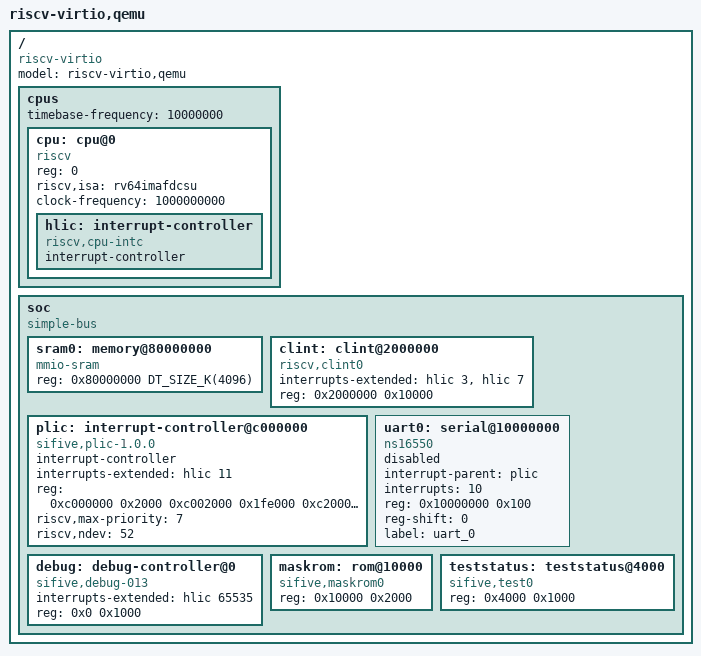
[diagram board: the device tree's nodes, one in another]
/* SPDX-License-Identifier: Apache-2.0 */

#include <mem.h>

/ {
	#address-cells = <1>;
	#size-cells = <1>;
	compatible = "riscv-virtio";
	model = "riscv-virtio,qemu";

	cpus {
		#address-cells = <1>;
		#size-cells = <0>;
		timebase-frequency = <10000000>;

		cpu: cpu@0 {
			device_type = "cpu";
			reg = <0>;
			status = "okay";
			compatible = "riscv";
			riscv,isa = "rv64imafdcsu";
			clock-frequency = <1000000000>;

			hlic: interrupt-controller {
				#interrupt-cells = <1>;
				interrupt-controller;
				compatible = "riscv,cpu-intc";
			};
		};
	};
	soc {
		#address-cells = <1>;
		#size-cells = <1>;
		compatible = "simple-bus";
		ranges;

		sram0: memory@80000000 {
			compatible = "mmio-sram";
			device_type = "memory";
			reg = <0x80000000 DT_SIZE_K(4096)>;
			reg-names = "mem";
		};
		clint: clint@2000000 {
			compatible = "riscv,clint0";
			interrupts-extended = <&hlic 3 &hlic 7>;
			reg = <0x2000000 0x10000>;
			reg-names = "control";
		};
		plic: interrupt-controller@c000000 {
			#interrupt-cells = <1>;
			compatible = "sifive,plic-1.0.0";
			interrupt-controller;
			interrupts-extended = <&hlic 11>;
			reg = <0xc000000 0x2000
			       0xc002000 0x1fe000
			       0xc200000 0x2000000>;
			reg-names = "prio", "irq_en", "reg";
			riscv,max-priority = <7>;
			riscv,ndev = <52>;
		};
		uart0: serial@10000000 {
			compatible = "ns16550";
			interrupt-parent = <&plic>;
			interrupts = <10>;
			reg = <0x10000000 0x100>;
			reg-shift = <0>;
			label = "uart_0";
			status = "disabled";
		};
		debug: debug-controller@0 {
			compatible = "sifive,debug-013", "riscv,debug-013";
			interrupts-extended = <&hlic 65535>;
			reg = <0x0 0x1000>;
			reg-names = "control";
		};
		maskrom: rom@10000 {
			compatible = "sifive,maskrom0";
			reg = <0x10000 0x2000>;
			reg-names = "mem";
		};
		teststatus: teststatus@4000 {
			compatible = "sifive,test0";
			reg = <0x4000 0x1000>;
			reg-names = "control";
		};
	};
};
